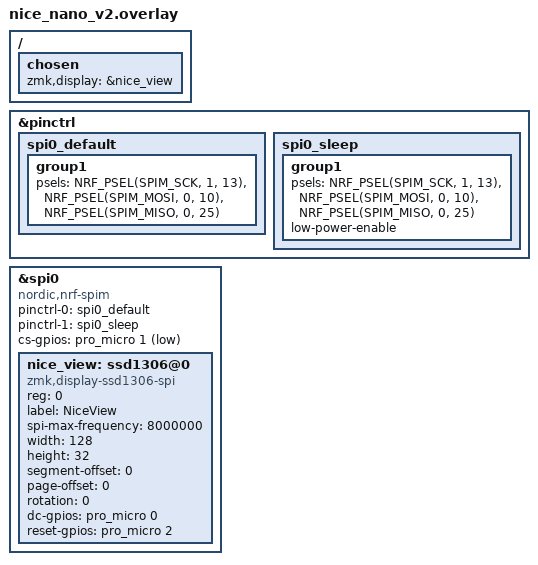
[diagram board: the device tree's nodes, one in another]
&pinctrl {
    spi0_default: spi0_default {
        group1 {
            psels = <NRF_PSEL(SPIM_SCK,  1, 13)>  // D15
                , <NRF_PSEL(SPIM_MOSI, 0, 10)>   // D16
                , <NRF_PSEL(SPIM_MISO, 0, 25)>   // unused, but fine
                ;
        };
    };
    spi0_sleep: spi0_sleep {
        group1 {
            psels = <NRF_PSEL(SPIM_SCK,  1, 13)>
                , <NRF_PSEL(SPIM_MOSI, 0, 10)>
                , <NRF_PSEL(SPIM_MISO, 0, 25)>
                ;
            low-power-enable;
        };
    };
};

&spi0 {
    compatible = "nordic,nrf-spim";
    status = "okay";
    pinctrl-0 = <&spi0_default>;
    pinctrl-1 = <&spi0_sleep>;
    pinctrl-names = "default", "sleep";

    cs-gpios = <&pro_micro 1 GPIO_ACTIVE_LOW>;

    nice_view: ssd1306@0 {
        compatible = "zmk,display-ssd1306-spi";
        reg = <0>;
        label = "NiceView";
        spi-max-frequency = <8000000>;
        width = <128>;
        height = <32>;
        segment-offset = <0>;
        page-offset = <0>;
        rotation = <0>;
        dc-gpios = <&pro_micro 0 GPIO_ACTIVE_HIGH>;
        reset-gpios = <&pro_micro 2 GPIO_ACTIVE_HIGH>;
    };
};

/ {
    chosen {
        zmk,display = &nice_view;
    };
};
